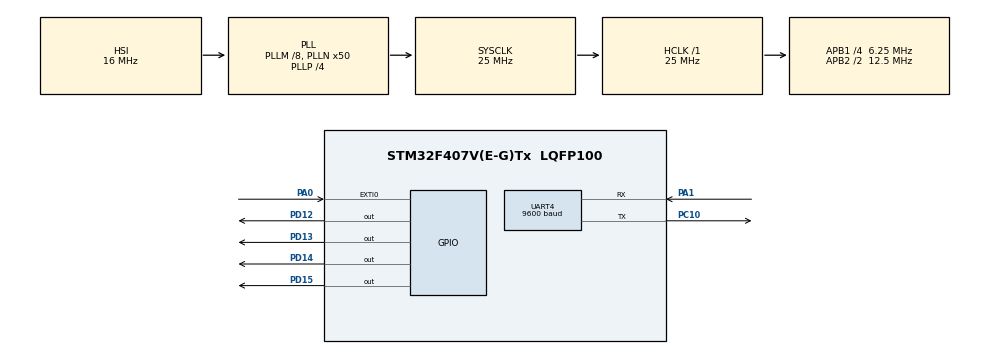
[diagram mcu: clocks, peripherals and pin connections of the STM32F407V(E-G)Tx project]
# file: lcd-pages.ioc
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Mcu.Family=STM32F4
Mcu.Name=STM32F407V(E-G)Tx
Mcu.Package=LQFP100
NVIC.PriorityGroup=NVIC_PRIORITYGROUP_0
NVIC.TIM1_UP_TIM10_IRQn=true\:0\:0\:false\:false\:true\:false\:true
NVIC.TimeBase=TIM1_UP_TIM10_IRQn
NVIC.TimeBaseIP=TIM1
PA0-WKUP.Signal=GPXTI0
PA1.Mode=Asynchronous
PA1.Signal=UART4_RX
PC10.Mode=Asynchronous
PC10.Signal=UART4_TX
PD12.Signal=GPIO_Output
PD13.Signal=GPIO_Output
PD14.Signal=GPIO_Output
PD15.Signal=GPIO_Output
ProjectManager.HeapSize=0x200
ProjectManager.StackSize=0x400
ProjectManager.TargetToolchain=STM32CubeIDE
RCC.48MHZClocksFreq_Value=14285714.285714285
RCC.AHBFreq_Value=25000000
RCC.APB1CLKDivider=RCC_HCLK_DIV4
RCC.APB1Freq_Value=6250000
RCC.APB1TimFreq_Value=12500000
RCC.APB2CLKDivider=RCC_HCLK_DIV2
RCC.APB2Freq_Value=12500000
RCC.APB2TimFreq_Value=25000000
RCC.CortexFreq_Value=25000000
RCC.HCLKFreq_Value=25000000
RCC.HSE_VALUE=8000000
RCC.HSI_VALUE=16000000
RCC.LSE_VALUE=32768
RCC.PLLM=8
RCC.PLLN=50
RCC.PLLP=RCC_PLLP_DIV4
RCC.PLLQ=7
RCC.SYSCLKFreq_VALUE=25000000
RCC.SYSCLKSource=RCC_SYSCLKSOURCE_PLLCLK
RCC.VCOOutputFreq_Value=100000000
UART4.BaudRate=9600
UART4.Mode=MODE_TX
UART4.VirtualMode=Asynchronous
VP_SYS_VS_tim1.Mode=TIM1
board=STM32F407G-DISC1

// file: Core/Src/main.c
/* USER CODE BEGIN Header */
/**
  ******************************************************************************
  * @file           : main.c
  * @brief          : Main program body
  ******************************************************************************
  * @attention
  *
  * <h2><center>&copy; Copyright (c) 2021 STMicroelectronics.
  * All rights reserved.</center></h2>
  *
  * This software component is licensed by ST under BSD 3-Clause license,
  * the "License"; You may not use this file except in compliance with the
  * License. You may obtain a copy of the License at:
  *                        opensource.org/licenses/BSD-3-Clause
  *
  ******************************************************************************
  */
/* USER CODE END Header */
#include "main.h"

/* USER CODE BEGIN Includes */
#include "lcd16x2.h"
/* USER CODE END Includes */

UART_HandleTypeDef huart4;

/* USER CODE BEGIN PV */
uint8_t startup_buffer[] = { 'h','e','l','l','o',' ','A','R','M'};
/* USER CODE END PV */

void SystemClock_Config(void);
static void MX_GPIO_Init(void);
static void MX_UART4_Init(void);

int main(void)
{

  /* MCU Configuration--------------------------------------------------------*/

  /* Reset of all peripherals, Initializes the Flash interface and the Systick. */
  HAL_Init();

  /* Configure the system clock */
  SystemClock_Config();

  /* Initialize all configured peripherals */
  MX_GPIO_Init();
  MX_UART4_Init();
  /* USER CODE BEGIN 2 */
  LCD_Init(&huart4);
  HAL_Delay(100);
//  LCD_Line2();
  HAL_UART_Transmit(&huart4, startup_buffer, 9, 500);
  /* USER CODE END 2 */

  /* Infinite loop */
  while (1)
  {

  }
}

void SystemClock_Config(void)
{
  RCC_OscInitTypeDef RCC_OscInitStruct = {0};
  RCC_ClkInitTypeDef RCC_ClkInitStruct = {0};

  /** Configure the main internal regulator output voltage
  */
  __HAL_RCC_PWR_CLK_ENABLE();
  __HAL_PWR_VOLTAGESCALING_CONFIG(PWR_REGULATOR_VOLTAGE_SCALE1);
  /** Initializes the RCC Oscillators according to the specified parameters
  * in the RCC_OscInitTypeDef structure.
  */
  RCC_OscInitStruct.OscillatorType = RCC_OSCILLATORTYPE_HSI;
  RCC_OscInitStruct.HSIState = RCC_HSI_ON;
  RCC_OscInitStruct.HSICalibrationValue = RCC_HSICALIBRATION_DEFAULT;
  RCC_OscInitStruct.PLL.PLLState = RCC_PLL_ON;
  RCC_OscInitStruct.PLL.PLLSource = RCC_PLLSOURCE_HSI;
  RCC_OscInitStruct.PLL.PLLM = 8;
  RCC_OscInitStruct.PLL.PLLN = 50;
  RCC_OscInitStruct.PLL.PLLP = RCC_PLLP_DIV4;
  RCC_OscInitStruct.PLL.PLLQ = 7;
  if (HAL_RCC_OscConfig(&RCC_OscInitStruct) != HAL_OK)
  {
    Error_Handler();
  }
  /** Initializes the CPU, AHB and APB buses clocks
  */
  RCC_ClkInitStruct.ClockType = RCC_CLOCKTYPE_HCLK|RCC_CLOCKTYPE_SYSCLK
                              |RCC_CLOCKTYPE_PCLK1|RCC_CLOCKTYPE_PCLK2;
  RCC_ClkInitStruct.SYSCLKSource = RCC_SYSCLKSOURCE_PLLCLK;
  RCC_ClkInitStruct.AHBCLKDivider = RCC_SYSCLK_DIV1;
  RCC_ClkInitStruct.APB1CLKDivider = RCC_HCLK_DIV4;
  RCC_ClkInitStruct.APB2CLKDivider = RCC_HCLK_DIV2;

  if (HAL_RCC_ClockConfig(&RCC_ClkInitStruct, FLASH_LATENCY_0) != HAL_OK)
  {
    Error_Handler();
  }
}

static void MX_UART4_Init(void)
{

  huart4.Instance = UART4;
  huart4.Init.BaudRate = 9600;
  huart4.Init.WordLength = UART_WORDLENGTH_8B;
  huart4.Init.StopBits = UART_STOPBITS_1;
  huart4.Init.Parity = UART_PARITY_NONE;
  huart4.Init.Mode = UART_MODE_TX;
  huart4.Init.HwFlowCtl = UART_HWCONTROL_NONE;
  huart4.Init.OverSampling = UART_OVERSAMPLING_16;
  if (HAL_UART_Init(&huart4) != HAL_OK)
  {
    Error_Handler();
  }

}

static void MX_GPIO_Init(void)
{
  GPIO_InitTypeDef GPIO_InitStruct = {0};

  /* GPIO Ports Clock Enable */
  __HAL_RCC_GPIOA_CLK_ENABLE();
  __HAL_RCC_GPIOD_CLK_ENABLE();
  __HAL_RCC_GPIOC_CLK_ENABLE();

  /*Configure GPIO pin Output Level */
  HAL_GPIO_WritePin(GPIOD, GPIO_PIN_12|GPIO_PIN_13|GPIO_PIN_14|GPIO_PIN_15, GPIO_PIN_RESET);

  /*Configure GPIO pin : PA0 */
  GPIO_InitStruct.Pin = GPIO_PIN_0;
  GPIO_InitStruct.Mode = GPIO_MODE_IT_RISING;
  GPIO_InitStruct.Pull = GPIO_NOPULL;
  HAL_GPIO_Init(GPIOA, &GPIO_InitStruct);

  /*Configure GPIO pins : PD12 PD13 PD14 PD15 */
  GPIO_InitStruct.Pin = GPIO_PIN_12|GPIO_PIN_13|GPIO_PIN_14|GPIO_PIN_15;
  GPIO_InitStruct.Mode = GPIO_MODE_OUTPUT_PP;
  GPIO_InitStruct.Pull = GPIO_NOPULL;
  GPIO_InitStruct.Speed = GPIO_SPEED_FREQ_LOW;
  HAL_GPIO_Init(GPIOD, &GPIO_InitStruct);

}

void HAL_TIM_PeriodElapsedCallback(TIM_HandleTypeDef *htim)
{
  if (htim->Instance == TIM1) {
    HAL_IncTick();
  }
}

void Error_Handler(void)
{
  __disable_irq();
  while (1)
  {
  }
}

/************************ (C) COPYRIGHT STMicroelectronics *****END OF FILE****/
